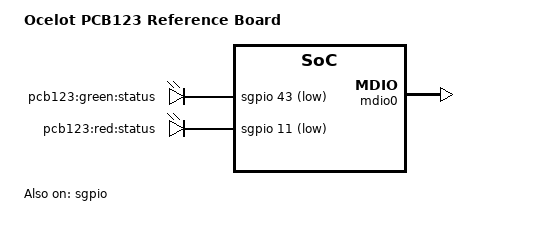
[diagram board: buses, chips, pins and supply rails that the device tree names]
// SPDX-License-Identifier: (GPL-2.0+ OR MIT)
/*
 * Copyright (c) 2018 Microsemi Corporation
 */

/dts-v1/;
#include "mscc,ocelot_pcb.dtsi"

/ {
	model = "Ocelot PCB123 Reference Board";
	compatible = "mscc,ocelot-pcb123", "mscc,ocelot";

	chosen {
		stdout-path = "serial0:115200n8";
	};

	gpio-leds {
		compatible = "gpio-leds";

		status_green {
			label = "pcb123:green:status";
			gpios = <&sgpio 43 1>; /* p11.1 */
			default-state = "on";
		};

		status_red {
			label = "pcb123:red:status";
			gpios = <&sgpio 11 1>; /* p11.0 */
			default-state = "off";
		};
	};
};

&sgpio {
	status = "okay";
	mscc,sgpio-ports = <0x00FFFFFF>;
};

&mdio0 {
	status = "okay";
};

&port0 {
	phy-handle = <&phy0>;
};

&port1 {
	phy-handle = <&phy1>;
};

&port2 {
	phy-handle = <&phy2>;
};

&port3 {
	phy-handle = <&phy3>;
};
